# AE822FA0E5597LS0_CM55_HE_View register map
Vendor: Alif Semiconductor; Series: E8; File version: 1.0
CPU: CM55 r1p0, selectable endian, MPU, FPU, double-precision FPU, DSP, VTOR, 8 interrupt priority bits, 1 SAU regions
Registers are 32-bit, read-write, reset 0x0 unless marked. A register's access mark holds for its fields unless they carry their own. Offsets are from the block's base; [hi:lo] are bit positions; {n}, {i} and the like mark numbered series.

## LPGPIO
Base 0x42002000
Same registers: GPIO16 0x4300A000, GPIO17 0x4300B000, LPGPIO_FAST 0x43010000, GPIO{n} {0x49000000+0x1000*n} (n=0..14)
0x00 GPIO_SWPORTA_DR — GPIO Port Data Register
  [7:0] GPIO_SWPORTA_DR — The values written to this field are output on the GPIO signals if the corresponding GPIO_SWPORTA_DDR[GPIO_SWPORTA_DDR] field is set to 1. The value read back is equal to the last value written to this field.
0x04 GPIO_SWPORTA_DDR — GPIO Port Data Direction Register
  [7:0] GPIO_SWPORTA_DDR — The values written to this field independently control the data direction of the corresponding GPIO signal. The direction is input after system reset by default.
    0=Input direction; 1=Output direction
0x08 GPIO_SWPORTA_CTL — GPIO Port Data Source Register
  [7:0] GPIO_SWPORTA_CTL — For GPIO: Only bit [0] is valid. Bit [0] setting specifies whether the data source for the entire port (all pins) is hardware (AUX port) or software (normal operation). When hardware mode is selected, this enables the 'bit manipulation' feature on the GPIO port, as per the configuration in the bit manipulation registers. Note: GPIO16 and GPIO17 support only software mode, so bit [0] should be set to 0. For LPGPIO: All bits [7-0] are valid. Individual bit values specify whether the data source for the corresponding pins is hardware (AUX port) or software (normal operation). When hardware mode is selected, this enables the LPTIMER I/O signals and/or LFXO/LFRC oscillator clock signals (LFXO_OUT/LFRC_OUT) to be routed on the LPGPIO pins through the AUX port. For LPGPIO_FAST: Only bit [0] is valid. Bit [0] setting specifies whether the data source for the entire port (all pins) is hardware (AUX port) or software (normal operation). Note: LPGPIO_FAST supports only software mode, so bit [0] should be set to 0.
    0=Software mode. Output data and direction control for the pins are sourced from GPIO_SWPORTA_DR and GPIO_SWPORTA_DDR registers, respectively. Input data can be read from the GPIO_EXT_PORTA register.; 1=Hardware mode
0x30 GPIO_INTEN — GPIO Port Interrupt Enable Register
  [7:0] GPIO_INTEN — Writing a 1 to a bit of this field configures the corresponding GPIO to become an interrupt signal. Interrupts are disabled on the corresponding bits if the corresponding bit of GPIO_SWPORTA_DDR[GPIO_SWPORTA_DDR] field is set to 1 (output). The generation of interrupts are disabled by default.
    0=Interrupt is disabled; 1=Interrupt is enabled
0x34 GPIO_INTMASK — GPIO Port Interrupt Mask Register
  [7:0] GPIO_INTMASK — Writing a 1 to a bit in this field masks the interrupt generation capability for this corresponding GPIO signal. Otherwise interrupts are allowed through. The unmasked status is read as well as the resultant status after masking. All interrupt bits are unmasked by default.
    0=Interrupt bits are unmasked; 1=Interrupt bits are masked
0x38 GPIO_INTTYPE_LEVEL — GPIO Port Interrupt Level Register
  [7:0] GPIO_INTTYPE_LEVEL — Writing a 0 to a bit of this field configures the interrupt type to be level-sensitive. Otherwise, it is edge-sensitive.
    0=Interrupt is level sensitive; 1=Interrupt is edge sensitive
0x3C GPIO_INT_POLARITY — GPIO Port Interrupt Polarity Register
  [7:0] GPIO_INT_POLARITY — Writing a 0 to a bit of this field configures the interrupt type to Falling edge or Active-low sensitive. Otherwise, it is Rising edge or Active-high sensitive.
    0=Active-low polarity / Falling edge; 1=Active-high polarity / Rising edge
0x40 GPIO_INTSTATUS ro — GPIO Port Interrupt Status Register
  [7:0] GPIO_INTSTATUS — Interrupt status after masks
    0=Inactive; 1=Active
0x44 GPIO_RAW_INTSTATUS ro — GPIO Port Raw Interrupt Status Register
  [7:0] GPIO_RAW_INTSTATUS — Raw interrupt status. This status is before masks.
    0=Inactive; 1=Active
0x48 GPIO_DEBOUNCE — GPIO Port Debounce Enable Register
  [7:0] GPIO_DEBOUNCE — Writing a 1 to a bit in this field enables the debouncing circuitry. A signal must be valid for two periods of the debounce clock before it is internally processed.
    0=No debounce; 1=Enable debounce
0x4C GPIO_PORTA_EOI wo — GPIO Port End Of Interrupt Register
  [7:0] GPIO_PORTA_EOI — Writing a 1 to a bit of this field, clears the corresponding interrupt.
    0=No interrupt clear; 1=Clear Interrupt
0x50 GPIO_EXT_PORTA ro — GPIO External Port Read Register
  [7:0] GPIO_EXT_PORTA — This register provides either the data on the GPIO pins or the contents of the GPIO_SWPORTA_DR, depending on the value of GPIO_SWPORTA_DDR.
0x60 GPIO_LS_SYNC — Synchronization Level Register
  [0] GPIO_LS_SYNC — Writing a 1 to this bit results in all level-sensitive interrupts being synchronized to PCLK_INTR. They are not synchronized to PCLK_INTR by default.
    0=No synchronization to PCLK_INTR; 1=Synchronize to PCLK_INTR
0x68 GPIO_INT_BOTHEDGE — GPIO Port Interrupt Both Edge Type Register
  [7:0] GPIO_INT_BOTHEDGE — Writing a 1 to a bit of this field enables the generation of interrupts on both the Rising edge and the Falling edge of an external input signal. The values programmed in the registers GPIO_INTTYPE_LEVEL and GPIO_INT_POLARITY for this particular bit are not considered when the corresponding bit of this field is set to 1. Writing a 0 to a bit of this field makes the interrupt type to depend on the value of the corresponding bits in the GPIO_INTTYPE_LEVEL and GPIO_INT_POLARITY registers.
    0=Single edge sensitive; 1=Both edge sensitive
0x6C GPIO_VER_ID_CODE ro reset 0x3231352A — GPIO Version ID Register
  [31:0] GPIO_VER_ID_CODE — Module version ID code
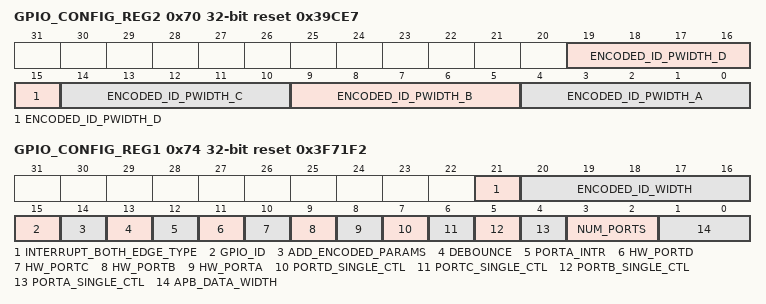
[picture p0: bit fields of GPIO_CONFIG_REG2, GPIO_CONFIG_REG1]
0x70 GPIO_CONFIG_REG2 ro reset 0x39CE7 — Module Configuration Register 2
  [19:15] ENCODED_ID_PWIDTH_D — Reserved for multi-port configuration
  [14:10] ENCODED_ID_PWIDTH_C — Reserved for multi-port configuration
  [9:5] ENCODED_ID_PWIDTH_B — Reserved for multi-port configuration
  [4:0] ENCODED_ID_PWIDTH_A
    7=Port is 8 bits wide
0x74 GPIO_CONFIG_REG1 ro reset 0x3F71F2 — Module Configuration Register 1
  [21] INTERRUPT_BOTH_EDGE_TYPE — The value of this bit defines the interrupt generation type.
    1=Interrupt generation on both rising and falling edge
  [20:16] ENCODED_ID_WIDTH — The value of this field defines the encoded ID width.
  [15] GPIO_ID — The value of this bit defines the GPIO ID.
    0=GPIO_ID not included
  [14] ADD_ENCODED_PARAMS — The value of this bit defines the encoded parameters.
    1=Encoded parameters added
  [13] DEBOUNCE — The value of this bit defines the debounce capability.
    1=Included debounce capability
  [12] PORTA_INTR — The value of this bit defines the Port A interrupts configuration.
    1=PORT A is required to be used as an interrupt
  [11] HW_PORTD — Reserved for multi-port configuration
  [10] HW_PORTC — Reserved for multi-port configuration
  [9] HW_PORTB — Reserved for multi-port configuration
  [8] HW_PORTA — The value of this bit defines the Port A hardware configuration.
    0=Port A has no external auxiliary hardware signals; 1=Port A has external auxiliary hardware signals
  [7] PORTD_SINGLE_CTL — Reserved for multi-port configuration
  [6] PORTC_SINGLE_CTL — Reserved for multi-port configuration
  [5] PORTB_SINGLE_CTL — Reserved for multi-port configuration
  [4] PORTA_SINGLE_CTL — The value of this bit defines the Port A single source configuration. NOTE: The reset value is: 0x1 for GPIO, LPGPIO_FAST; 0x0 for LPGPIO.
    0=Port A is controlled from two sources; 1=Port A is controlled from a single source
  [3:2] NUM_PORTS — The value of this field defines the number of ports.
    0=Number of ports is 1
  [1:0] APB_DATA_WIDTH — The value of this field defines the APB data width.
    2=APB data width is 32 bits
0x100 GPIO_BIT_MAN_CTRL — Bit Manipulation Control Register
  [7:0] AUX_PORTA_OUT — Direct control value to output port. This value is directly reflected on the device pins.
0x104 GPIO_BIT_MAN_CTRL_W1C wo — Bit Manipulation Control Register - Write 1 to Clear
  [7:0] AUX_PORTA_OUT_W1C write-1-clears — Write 1 to clear (to 0) an output pin. Write 0: no action on output pin. Reads return last value written to this register.
0x108 GPIO_BIT_MAN_CTRL_W1F wo — Bit Manipulation Control Register - Write 1 to Toggle
  [7:0] AUX_PORTA_OUT_W1F write-1-toggles — Write 1 to toggle (flip) an output pin. Write 0: no action on output pin. Reads return last value written to this register.
0x10C GPIO_BIT_MAN_CTRL_W1S wo — Bit Manipulation Control Register - Write 1 to Set
  [7:0] AUX_PORTA_OUT_W1S write-1-sets — Write 1 to set (to 1) an output pin. Write 0: no action on output pin. Reads return last value written to this register.
